# PCIE0_CPTS register map
Vendor: Texas Instruments
Peripheral module from a debugger description file (folder am65x).
Registers are 32-bit, read-write, reset 0x0 unless marked. A register's access mark holds for its fields unless they carry their own. Offsets are as the file gives them; lines under a group give offsets from that group; [hi:lo] are bit positions; {n}, {i} and the like mark numbered series; 'fields as' and 'values as' point back to an identical list; <NAME> marks a mode.

## PCIE0_CPTS
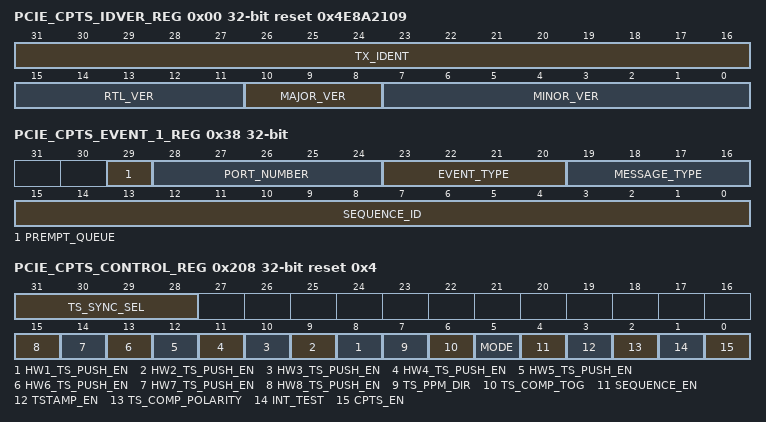
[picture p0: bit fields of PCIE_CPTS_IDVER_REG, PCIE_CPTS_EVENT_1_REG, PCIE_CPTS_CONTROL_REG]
0x00 PCIE_CPTS_IDVER_REG ro reset 0x4E8A2109 — Identification and Version Register
  [31:16] TX_IDENT — Identification value
  [15:11] RTL_VER — RTL version value
  [10:8] MAJOR_VER — Major version value
  [7:0] MINOR_VER — Minor version value
0x08 PCIE_CPTS_RFTCLK_SEL_REG — Added PCIE_CPTS_RFTCLK_SEL Register Bit Field Description RFTCLK Select Register
  [4:0] RFTCLK_SEL — Reference clock select. This bit field is used to control an external multiplexer that selects one out of 8 clocks for time sync reference. 0h: Selects CPSWHSDIV_CLKOUT2 clock 1h: Selects MAINHSDIV_CLKOUT3 clock 2h: Selects MCU_CPTS0_RFT_CLK I/O pin 3h: Selects CPTS0_RFT_CLK I/O pin 4h: Selects MCU_EXT_REFCLK0 I/O pin 5h: Selects EXT_REFCLK1 I/O pin 6h: Selects PCIE0_TXI0_CLK clock 7h: Selects PCIE1_TXI0_CLK clock The RFTCLK_SEL value can be written only when the [0] CPTS_EN and [3] TSTAMP_EN bits are cleared to zero in the PCIE_CPTS_CONTROL_REG register.
0x0C PCIE_CPTS_TS_PUSH_REG wo — Time Stamp Event Push Register
  [0] TS_PUSH — Time stamp event push
0x10 PCIE_CPTS_TS_LOAD_VAL_REG — Time Stamp Load Low Value Register
  [31:0] TS_LOAD_VAL — Time stamp load low value
0x14 PCIE_CPTS_TS_LOAD_EN_REG wo — Time Stamp Load Enable Register
  [0] TS_LOAD_EN — Time stamp load enable
0x18 PCIE_CPTS_TS_COMP_VAL_REG — Time Stamp Comparison Low Value Register
  [31:0] TS_COMP_VAL — Time stamp comparison low value
0x1C PCIE_CPTS_TS_COMP_LEN_REG — Time Stamp Comparison Length Register
  [31:0] TS_COMP_LENGTH — Time stamp comparison length
0x20 PCIE_CPTS_INTSTAT_RAW_REG — Interrupt Status Register Raw
  [0] TS_PEND_RAW — TS_PEND_RAW int read (before enable)
0x24 PCIE_CPTS_INTSTAT_MASKED_REG ro — Interrupt Status Register Masked
  [0] TS_PEND — TS_PEND masked interrupt read (after enable)
0x28 PCIE_CPTS_INT_ENABLE_REG — Interrupt Enable Register
  [0] TS_PEND_EN — TS_PEND masked interrupt enable
0x2C PCIE_CPTS_TS_COMP_NUDGE_REG — Time Stamp Comparison Nudge Register
  [7:0] NUDGE — This 2s complement number is added to the ts_comp_length value to increase or decrease the TS_COMP length by the nudge amount
0x30 PCIE_CPTS_EVENT_POP_REG wo — Event Pop Register
  [0] EVENT_POP
0x34 PCIE_CPTS_EVENT_0_REG ro — Event 0 Register
  [31:0] TIME_STAMP
0x38 PCIE_CPTS_EVENT_1_REG ro — Event 1 Register
  [29] PREMPT_QUEUE, [28:24] PORT_NUMBER, [23:20] EVENT_TYPE, [19:16] MESSAGE_TYPE, [15:0] SEQUENCE_ID
0x3C PCIE_CPTS_EVENT_2_REG ro — Event 2 Register
  [7:0] DOMAIN
0x40 PCIE_CPTS_EVENT_3_REG ro — Event 3 Register
  [31:0] TIME_STAMP
0x44 PCIE_CPTS_TS_LOAD_HIGH_VAL_REG — Time Stamp Load High Value Register
  [31:0] TS_LOAD_VAL — Time stamp load high value
0x48 PCIE_CPTS_TS_COMP_HIGH_VAL_REG — Time Stamp Comparison High Value Register
  [31:0] TS_COMP_HIGH_VAL — Time stamp comparison high value
0x4C PCIE_CPTS_TS_ADD_VAL_REG — TS Add Value Register
  [2:0] ADD_VAL — Add Value
0x50 PCIE_CPTS_TS_PPM_LOW_VAL_REG — Time Stamp PPM Low Value Register
  [31:0] TS_PPM_LOW_VAL — Time stamp PPM Low value
0x54 PCIE_CPTS_TS_PPM_HIGH_VAL_REG — Time Stamp PPM High Value Register
  [9:0] TS_PPM_HIGH_VAL — Time stamp PPM High value
0x58 PCIE_CPTS_TS_NUDGE_VAL_REG — Time Stamp Nudge Value Register
  [7:0] TS_NUDGE_VAL — Time stamp Nudge value
0x200 PCIE_CPTS_COMP_LOW_REG — Time Stamp Generate Function Comparison Low Value
  [31:0] COMP_LOW
0x204 PCIE_CPTS_COMP_HIGH_REG — Time Stamp Generate Function Comparison high Value
  [31:0] COMP_HIGH — Time Stamp Generate Function Comparison High Value
0x208 PCIE_CPTS_CONTROL_REG reset 0x4 — Time Sync Control Register
  [31:28] TS_SYNC_SEL — TS_SYNC output timestamp counter bit select
  [n+7] HW{n}_TS_PUSH_EN (n=1..8) — Hardware push {n} enable
  [7] TS_PPM_DIR — Timestamp PPM Direction
  [6] TS_COMP_TOG — Timestamp Compare Toggle mode: 0=TS_COMP is in non-toggle mode, 1=TS_COMP is in toggle mode
  [5] MODE — Timestamp mode
  [4] SEQUENCE_EN — Sequence Enable
  [3] TSTAMP_EN — Host Receive Timestamp Enable
  [2] TS_COMP_POLARITY
  [1] INT_TEST — Interrupt test
  [0] CPTS_EN — Time sync enable
0x20C PCIE_CPTS_LENGTH_REG — Time Stamp Generate Function Length Value
  [31:0] LENGTH
0x210 PCIE_CPTS_PPM_LOW_REG — Time Stamp Generate Function PPM Low Value
  [31:0] PPM_LOW
0x214 PCIE_CPTS_PPM_HIGH_REG — Time Stamp Generate Function PPM High Value
  [9:0] PPM_HIGH
0x218 PCIE_CPTS_NUDGE_REG — Time Stamp Generate Function Nudge Value
  [7:0] NUDGE
